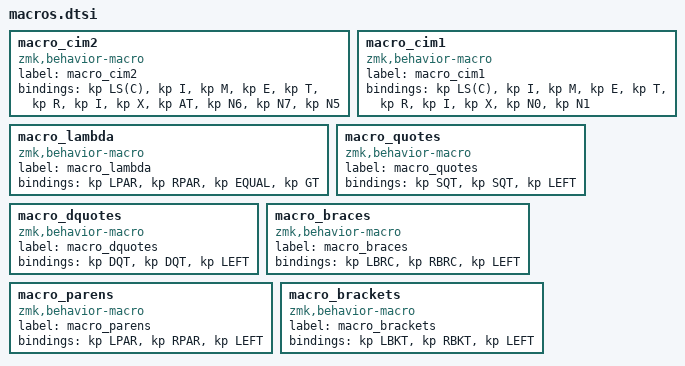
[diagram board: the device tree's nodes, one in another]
macro_cim2: macro_cim2{
compatible = "zmk,behavior-macro";
label = "macro_cim2";
#binding-cells = <0>;
bindings = <&kp LS(C)>, <&kp I>, <&kp M>, <&kp E>, <&kp T>, <&kp R>, <&kp I>, <&kp X>, <&kp AT>, <&kp N6>, <&kp N7>, <&kp N5>;
};
macro_cim1: macro_cim1{
compatible = "zmk,behavior-macro";
label = "macro_cim1";
#binding-cells = <0>;
bindings = <&kp LS(C)>, <&kp I>, <&kp M>, <&kp E>, <&kp T>, <&kp R>, <&kp I>, <&kp X>, <&kp N0>, <&kp N1>;
};
macro_lambda: macro_lambda{
compatible = "zmk,behavior-macro";
label = "macro_lambda";
#binding-cells = <0>;
bindings = <&kp LPAR>, <&kp RPAR>, <&kp EQUAL>, <&kp GT>;
};
macro_quotes: macro_quotes{
compatible = "zmk,behavior-macro";
label = "macro_quotes";
#binding-cells = <0>;
bindings = <&kp SQT>, <&kp SQT>, <&kp LEFT>;
};
macro_dquotes: macro_dquotes{
compatible = "zmk,behavior-macro";
label = "macro_dquotes";
#binding-cells = <0>;
bindings = <&kp DQT>, <&kp DQT>, <&kp LEFT>;
};
macro_braces: macro_braces{
compatible = "zmk,behavior-macro";
label = "macro_braces";
#binding-cells = <0>;
bindings = <&kp LBRC>, <&kp RBRC>, <&kp LEFT>;
};
macro_parens: macro_parens{
compatible = "zmk,behavior-macro";
label = "macro_parens";
#binding-cells = <0>;
bindings = <&kp LPAR>, <&kp RPAR>, <&kp LEFT>;
};
macro_brackets: macro_brackets{
compatible = "zmk,behavior-macro";
label = "macro_brackets";
#binding-cells = <0>;
bindings = <&kp LBKT>, <&kp RBKT>, <&kp LEFT>;
};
